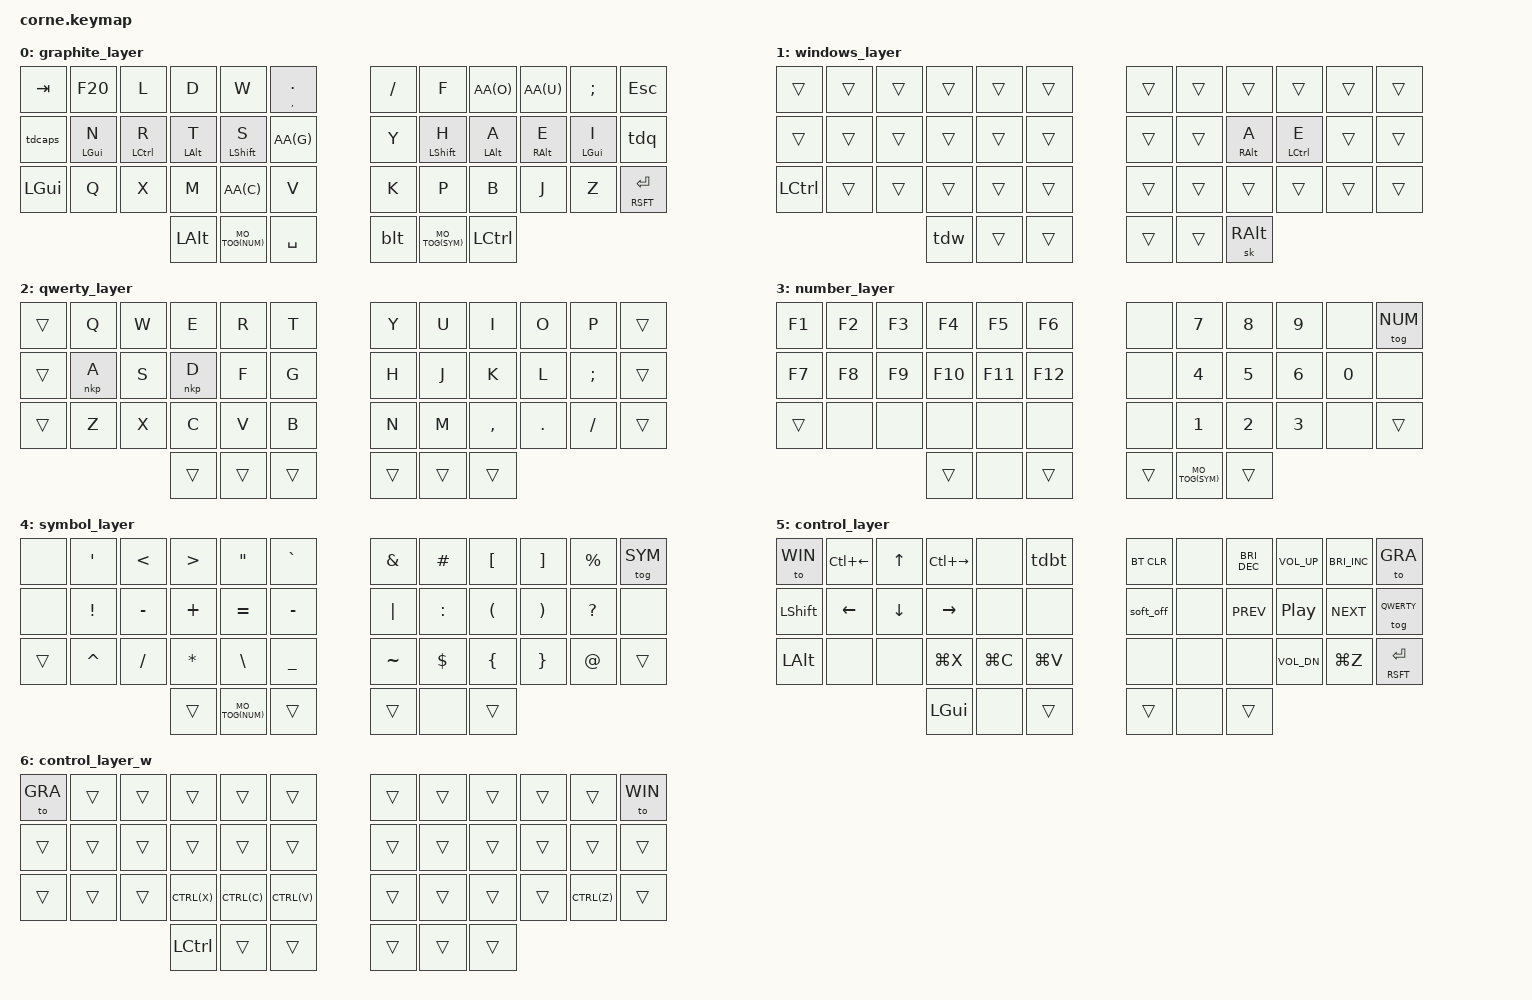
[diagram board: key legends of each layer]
/*
 * Copyright (c) 2020 The ZMK Contributors
 *
 * SPDX-License-Identifier: MIT
 */

#include <behaviors.dtsi>
#include <dt-bindings/zmk/keys.h>
#include <dt-bindings/zmk/bt.h>
#include <behaviors/non_overlap.dtsi>

#define GRA 0
#define WIN 1
#define QWERTY 2
#define NUM 3
#define SYM 4
#define CONTROL 5
#define CONTROLW 6

#define MO_TOG(layer) &mo_tog layer layer
#define AA(keycode) &ht_tp RA(keycode) keycode
#define CTRL(keycode) &ht_tp LG(keycode) LC(keycode)


//=========================//=========================/ Version: 7.3 /=========================//=========================//

/ {
    conditional_layers {
        compatible = "zmk,conditional-layers";
        control_layer {
            if-layers = <3 4>;
            then-layer = <5>;
        };
        
        control_layer_w {
            if-layers = <1 5>;
            then-layer = <6>;
        };
    };
};

&mt {
    flavor = "tap-preferred";
    tapping-term-ms = <240>;
};

&soft_off {
    hold-time-ms = <5000>; // Only turn off it the key is held for 5 seconds or longer.
};

/ {
        behaviors {

        //==================== TAP DANCES ====================//
                tdq: tap_dance_quotation {
                        compatible = "zmk,behavior-tap-dance";
                        #binding-cells = <0>;
                        tapping-term-ms = <200>;
                        bindings = <&kp SQT>, <&kp DQT>;
                };

                tdw: tap_dance_alt_win {
                        compatible = "zmk,behavior-tap-dance";
                        #binding-cells = <0>;
                        tapping-term-ms = <250>;
                        bindings = <&kp LALT>, <&kp LGUI>, <&kp LG(LALT)>;
                };

                tdcaps: tap_dance_shift_caps {
                        compatible = "zmk,behavior-tap-dance";
                        #binding-cells = <0>;
                        tapping-term-ms = <200>;
                        bindings = <&kp LSHFT>, <&kp CAPS>;
                };
                

                tdbt: tap_dance_bluetooth {
                        compatible = "zmk,behavior-tap-dance";
                        #binding-cells = <0>;
                        tapping-term-ms = <200>;
                        bindings = <&bt BT_SEL 0>, <&bt BT_SEL 1>, <&bt BT_SEL 2>;
                };

        //==================== HOLD TAPS ====================//
                mo_tog: behavior_mo_tog {
                      compatible = "zmk,behavior-hold-tap";
                        #binding-cells = <2>;
                        flavor = "hold-preferred";
                        tapping-term-ms = <200>;
                        bindings = <&mo>, <&tog>;
                };

                ht_tp: behavior_tap_preferred {
                        compatible = "zmk,behavior-hold-tap";
                        #binding-cells = <2>;
                        tapping_term_ms = <240>;
                        quick_tap_ms = <0>;
                        flavor = "tap-preferred";
                        bindings = <&kp>, <&kp>;
                };

        //==================== MOD MORPH ====================//
                blt: backspace_delete {
                        compatible = "zmk,behavior-mod-morph";
                        #binding-cells = <0>;
                        bindings = <&kp BSPC>, <&kp DEL>;
                        mods = <(MOD_LALT|MOD_RALT)>;
                };
        };

        keymap {
                compatible = "zmk,keymap";

                graphite_layer {
                         bindings = <
                         
   &kp TAB    &kp F20     &kp L        &kp D       &kp W        &ht_tp COMMA DOT     &kp FSLH  &kp F         AA(O)       AA(U)       &kp SEMI    &kp ESC
   &tdcaps    &mt LGUI N  &mt LCTRL R  &mt LALT T  &mt LSHFT S  AA(G)                &kp Y     &mt LSHFT H   &mt LALT A  &mt RALT E  &mt LGUI I  &tdq
   &kp LGUI   &kp Q       &kp X        &kp M       AA(C)        &kp V                &kp K     &kp P         &kp B       &kp J       &kp Z       &mt RSFT RET
                                       &kp LALT    MO_TOG(NUM)  &kp SPACE            &blt      MO_TOG(SYM)   &kp LCTRL
                        >;
                };

                windows_layer {
                         bindings = <
                         
   &trans     &trans    &trans    &trans    &trans    &trans        &trans      &trans    &trans      &trans       &trans    &trans
   &trans     &trans    &trans    &trans    &trans    &trans        &trans      &trans    &mt RALT A  &mt LCTRL E  &trans    &trans
   &kp LCTRL  &trans    &trans    &trans    &trans    &trans        &trans      &trans    &trans      &trans       &trans    &trans
                                  &tdw      &trans    &trans        &trans      &trans    &sk RALT
                        >;
                };

                qwerty_layer {
                         bindings = <
                         
   &trans    &kp Q    &kp W     &kp E     &kp R      &kp T         &kp Y     &kp U     &kp I      &kp O    &kp P     &trans
   &trans    &nkp A   &kp S     &nkp D    &kp F      &kp G         &kp H     &kp J     &kp K      &kp L    &kp SEMI  &trans
   &trans    &kp Z    &kp X     &kp C     &kp V      &kp B         &kp N     &kp M     &kp COMMA  &kp DOT  &kp FSLH  &trans
                                &trans    &trans     &trans        &trans    &trans    &trans
                        >;
                };

                number_layer {
                        bindings = <

   &kp F1     &kp F2    &kp F3    &kp F4     &kp F5     &kp F6         &none     &kp N7       &kp N8    &kp N9    &none     &tog NUM
   &kp F7     &kp F8    &kp F9    &kp F10    &kp F11    &kp F12        &none     &kp N4       &kp N5    &kp N6    &kp N0    &none
   &trans     &none     &none     &none      &none      &none          &none     &kp N1       &kp N2    &kp N3    &none     &trans
                                  &trans     &none      &trans         &trans    MO_TOG(SYM)  &trans
                        >;
                };

                symbol_layer {
                        bindings = <

   &none    &kp SQT    &kp LT     &kp GT    &kp DQT      &kp GRAVE        &kp AMPS    &kp HASH    &kp LBKT    &kp RBKT    &kp PRCNT  &tog SYM
   &none    &kp EXCL   &kp MINUS  &kp PLUS  &kp EQUAL    &kp MINUS        &kp PIPE    &kp COLON   &kp LPAR    &kp RPAR    &kp QMARK  &none
   &trans   &kp CARET  &kp FSLH   &kp STAR  &kp BSLH     &kp UNDER        &kp TILDE   &kp DLLR    &kp LBRC    &kp RBRC    &kp AT     &trans
                                  &trans    MO_TOG(NUM)  &trans           &trans      &none       &trans
                        >;
                };

                control_layer {
                        bindings = <

   &to WIN    &kp LC(LEFT)  &kp UP    &kp LC(RIGHT)  &none       &tdbt          &bt BT_CLR  &none     &kp C_BRI_DEC  &kp C_VOL_UP  &kp C_BRI_INC  &to GRA
   &kp LSHFT  &kp LEFT      &kp DOWN  &kp RIGHT      &none       &none          &soft_off   &none     &kp C_PREV     &kp C_PP      &kp C_NEXT     &tog QWERTY
   &kp LALT   &none         &none     &kp LG(X)      &kp LG(C)   &kp LG(V)      &none       &none     &none          &kp C_VOL_DN  &kp LG(Z)      &mt RSFT RET
                                      &kp LGUI       &none       &trans         &trans      &none     &trans
                        >;
                };

                control_layer_w {
                        bindings = <

   &to GRA    &trans    &trans    &trans     &trans    &trans         &trans    &trans    &trans    &trans    &trans    &to WIN
   &trans     &trans    &trans    &trans     &trans    &trans         &trans    &trans    &trans    &trans    &trans    &trans
   &trans     &trans    &trans    CTRL(X)    CTRL(C)   CTRL(V)        &trans    &trans    &trans    &trans    CTRL(Z)   &trans
                                  &kp LCTRL  &trans    &trans         &trans    &trans    &trans
                        >;
                };

        };
};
